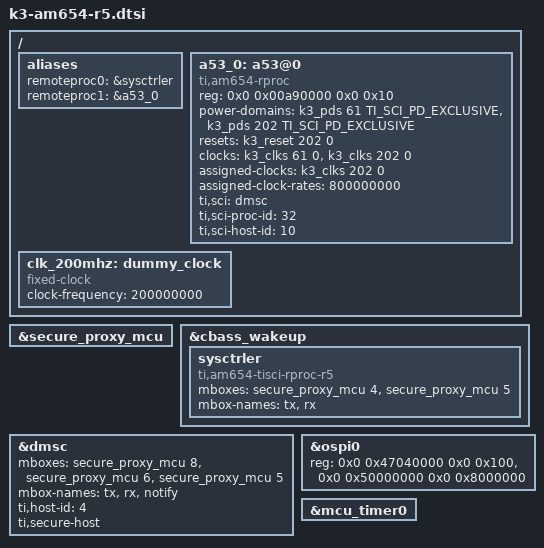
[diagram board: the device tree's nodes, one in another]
// SPDX-License-Identifier: GPL-2.0
/*
 * Copyright (C) 2026 Texas Instruments Incorporated - https://www.ti.com/
 */

/ {
	aliases {
		remoteproc0 = &sysctrler;
		remoteproc1 = &a53_0;
	};

	a53_0: a53@0 {
		compatible = "ti,am654-rproc";
		reg = <0x0 0x00a90000 0x0 0x10>;
		power-domains = <&k3_pds 61 TI_SCI_PD_EXCLUSIVE>,
				<&k3_pds 202 TI_SCI_PD_EXCLUSIVE>;
		resets = <&k3_reset 202 0>;
		clocks = <&k3_clks 61 0>, <&k3_clks 202 0>;
		clock-names = "gtc", "core";
		assigned-clocks = <&k3_clks 202 0>;
		assigned-clock-rates = <800000000>;
		ti,sci = <&dmsc>;
		ti,sci-proc-id = <32>;
		ti,sci-host-id = <10>;
		bootph-pre-ram;
	};

	clk_200mhz: dummy_clock {
		compatible = "fixed-clock";
		#clock-cells = <0>;
		clock-frequency = <200000000>;
		bootph-pre-ram;
	};
};

&secure_proxy_mcu {
	status = "okay";
	bootph-pre-ram;
};

&cbass_wakeup {
	sysctrler: sysctrler {
		compatible = "ti,am654-tisci-rproc-r5";
		mboxes= <&secure_proxy_mcu 4>, <&secure_proxy_mcu 5>;
		mbox-names = "tx", "rx";
		bootph-pre-ram;
	};
};

&dmsc {
	mboxes = <&secure_proxy_mcu 8>,
		 <&secure_proxy_mcu 6>,
		 <&secure_proxy_mcu 5>;
	mbox-names = "tx", "rx", "notify";
	ti,host-id = <4>;
	ti,secure-host;
};

&ospi0 {
	reg = <0x0 0x47040000 0x0 0x100>,
	      <0x0 0x50000000 0x0 0x8000000>;
};

/*
 * timer init is called as part of rproc_start() while
 * starting System Firmware, so any clock/power-domain
 * operations will fail as SYSFW is not yet up and running.
 * Delete all clock/power-domain properties to avoid
 * timer init failure.
 * This is an always on timer at 20MHz.
 */
&mcu_timer0 {
	/delete-property/ clocks;
	/delete-property/ assigned-clocks;
	/delete-property/ assigned-clock-parents;
	/delete-property/ power-domains;
};
